AUTOSAR XML (schema 3.1.2)
package /Components/SWC_FARSp
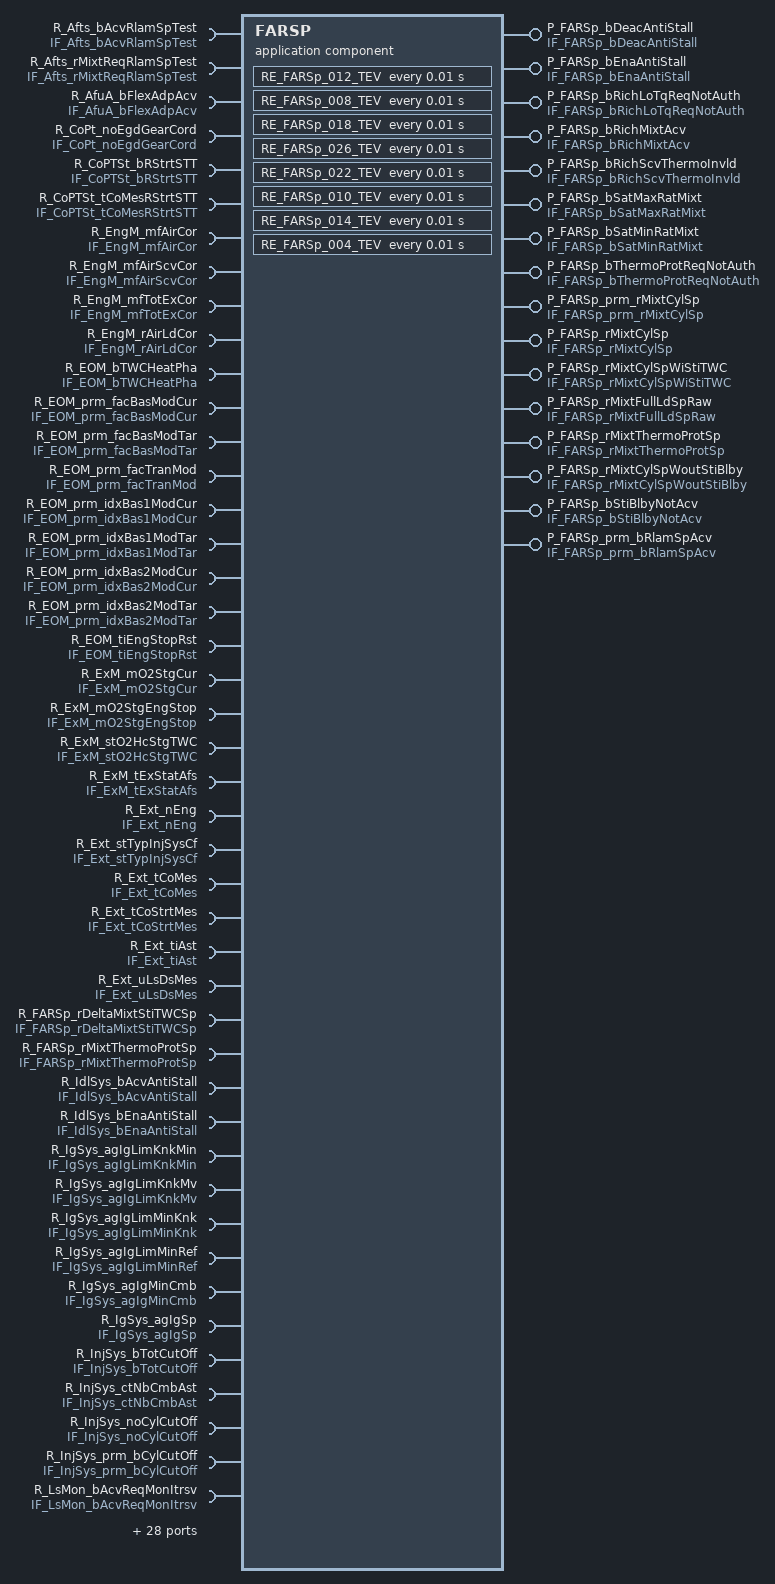
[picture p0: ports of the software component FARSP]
  application software component type FARSP
    71 x require port:
      R_Afts_bAcvRlamSpTest: unqueued-receiver-com-spec{data-element=Afts_bAcvRlamSpTest, init-value=ConstantValue, resync-time=0}, required-interface=IF_Afts_bAcvRlamSpTest  # Receiver of interface IF_Afts_bAcvRlamSpTest - Requirement Reference: [01552_10_01542-FARSp-I145(0)]
      R_Afts_rMixtReqRlamSpTest: unqueued-receiver-com-spec{data-element=Afts_rMixtReqRlamSpTest, init-value=ConstantValue1, resync-time=0}, required-interface=IF_Afts_rMixtReqRlamSpTest  # Receiver of interface IF_Afts_rMixtReqRlamSpTest - Requirement Reference: [01552_10_01542-FARSp-I144(0)]
      R_AfuA_bFlexAdpAcv: unqueued-receiver-com-spec{data-element=AfuA_bFlexAdpAcv, init-value=ConstantValue3, resync-time=0}, required-interface=IF_AfuA_bFlexAdpAcv  # Receiver of interface IF_AfuA_bFlexAdpAcv - Requirement Reference: [01552_10_01542-FARSp-I036(0)]
      R_CoPt_noEgdGearCord: unqueued-receiver-com-spec{data-element=CoPt_noEgdGearCord, init-value=ConstantValue5, resync-time=0}, required-interface=IF_CoPt_noEgdGearCord  # Receiver of interface IF_CoPt_noEgdGearCord - Requirement Reference: [01552_10_01542-FARSp-I099(0)]
      R_CoPTSt_bRStrtSTT: unqueued-receiver-com-spec{data-element=CoPTSt_bRStrtSTT, init-value=ConstantValue7, resync-time=0}, required-interface=IF_CoPTSt_bRStrtSTT  # Receiver of interface IF_CoPTSt_bRStrtSTT - Requirement Reference: [01552_10_01542-FARSp-I043(0)]
      R_CoPTSt_tCoMesRStrtSTT: unqueued-receiver-com-spec{data-element=CoPTSt_tCoMesRStrtSTT, init-value=ConstantValue9, resync-time=0}, required-interface=IF_CoPTSt_tCoMesRStrtSTT  # Receiver of interface IF_CoPTSt_tCoMesRStrtSTT - Requirement Reference: [01552_10_01542-FARSp-I044(1)]
      R_EngM_mfAirCor: unqueued-receiver-com-spec{data-element=EngM_mfAirCor, init-value=ConstantValue11, resync-time=0}, required-interface=IF_EngM_mfAirCor  # Receiver of interface IF_EngM_mfAirCor - Requirement Reference: [01552_10_01542-FARSp-I004(2)]
      R_EngM_mfAirScvCor: unqueued-receiver-com-spec{data-element=EngM_mfAirScvCor, init-value=ConstantValue13, resync-time=0}, required-interface=IF_EngM_mfAirScvCor  # Receiver of interface IF_EngM_mfAirScvCor - Requirement Reference: [01552_10_01542-FARSp-I005(2)]
      R_EngM_mfTotExCor: unqueued-receiver-com-spec{data-element=EngM_mfTotExCor, init-value=ConstantValue15, resync-time=0}, required-interface=IF_EngM_mfTotExCor  # Receiver of interface IF_EngM_mfTotExCor - Requirement Reference: [01552_10_01542-FARSp-I015(0)]
      R_EngM_rAirLdCor: unqueued-receiver-com-spec{data-element=EngM_rAirLdCor, init-value=ConstantValue17, resync-time=0}, required-interface=IF_EngM_rAirLdCor  # Receiver of interface IF_EngM_rAirLdCor - Requirement Reference: [01552_10_01542-FARSp-I006(1)]
      R_EOM_bTWCHeatPha: unqueued-receiver-com-spec{data-element=EOM_bTWCHeatPha, init-value=ConstantValue19, resync-time=0}, required-interface=IF_EOM_bTWCHeatPha  # Receiver of interface IF_EOM_bTWCHeatPha - Requirement Reference: [01552_10_01542-FARSp-I053(0)]
      R_EOM_prm_facBasModCur: unqueued-receiver-com-spec{data-element=EOM_prm_facBasModCur, init-value=ArrayConstantValue, resync-time=0}, required-interface=IF_EOM_prm_facBasModCur  # Receiver of interface IF_EOM_prm_facBasModCur - Requirement Reference: [01552_10_01542-FARSp-I054(2)]
      R_EOM_prm_facBasModTar: unqueued-receiver-com-spec{data-element=EOM_prm_facBasModTar, init-value=ArrayConstantValue21, resync-time=0}, required-interface=IF_EOM_prm_facBasModTar  # Receiver of interface IF_EOM_prm_facBasModTar - Requirement Reference: [01552_10_01542-FARSp-I055(2)]
      R_EOM_prm_facTranMod: unqueued-receiver-com-spec{data-element=EOM_prm_facTranMod, init-value=ArrayConstantValue23, resync-time=0}, required-interface=IF_EOM_prm_facTranMod  # Receiver of interface IF_EOM_prm_facTranMod - Requirement Reference: [01552_10_01542-FARSp-I056(2)]
      R_EOM_prm_idxBas1ModCur: unqueued-receiver-com-spec{data-element=EOM_prm_idxBas1ModCur, init-value=ArrayConstantValue25, resync-time=0}, required-interface=IF_EOM_prm_idxBas1ModCur  # Receiver of interface IF_EOM_prm_idxBas1ModCur - Requirement Reference: [01552_10_01542-FARSp-I057(1)]
      R_EOM_prm_idxBas1ModTar: unqueued-receiver-com-spec{data-element=EOM_prm_idxBas1ModTar, init-value=ArrayConstantValue27, resync-time=0}, required-interface=IF_EOM_prm_idxBas1ModTar  # Receiver of interface IF_EOM_prm_idxBas1ModTar - Requirement Reference: [01552_10_01542-FARSp-I058(1)]
      R_EOM_prm_idxBas2ModCur: unqueued-receiver-com-spec{data-element=EOM_prm_idxBas2ModCur, init-value=ArrayConstantValue29, resync-time=0}, required-interface=IF_EOM_prm_idxBas2ModCur  # Receiver of interface IF_EOM_prm_idxBas2ModCur - Requirement Reference: [01552_10_01542-FARSp-I059(1)]
      R_EOM_prm_idxBas2ModTar: unqueued-receiver-com-spec{data-element=EOM_prm_idxBas2ModTar, init-value=ArrayConstantValue31, resync-time=0}, required-interface=IF_EOM_prm_idxBas2ModTar  # Receiver of interface IF_EOM_prm_idxBas2ModTar - Requirement Reference: [01552_10_01542-FARSp-I060(1)]
      R_EOM_tiEngStopRst: unqueued-receiver-com-spec{data-element=EOM_tiEngStopRst, init-value=ConstantValue33, resync-time=0}, required-interface=IF_EOM_tiEngStopRst  # Receiver of interface IF_EOM_tiEngStopRst - Requirement Reference: [01552_10_01542-FARSp-I042(2)]
      R_ExM_mO2StgCur: unqueued-receiver-com-spec{data-element=ExM_mO2StgCur, init-value=ConstantValue35, resync-time=0}, required-interface=IF_ExM_mO2StgCur  # Receiver of interface IF_ExM_mO2StgCur - Requirement Reference: [01552_10_01542-FARSp-I081(0)]
      R_ExM_mO2StgEngStop: unqueued-receiver-com-spec{data-element=ExM_mO2StgEngStop, init-value=ConstantValue37, resync-time=0}, required-interface=IF_ExM_mO2StgEngStop  # Receiver of interface IF_ExM_mO2StgEngStop - Requirement Reference: [01552_10_01542-FARSp-I082(0)]
      R_ExM_stO2HcStgTWC: unqueued-receiver-com-spec{data-element=ExM_stO2HcStgTWC, init-value=ConstantValue39, resync-time=0}, required-interface=IF_ExM_stO2HcStgTWC  # Receiver of interface IF_ExM_stO2HcStgTWC - Requirement Reference: [01552_10_01542-FARSp-I016(0)]
      R_ExM_tExStatAfs: unqueued-receiver-com-spec{data-element=ExM_tExStatAfs, init-value=ConstantValue41, resync-time=0}, required-interface=IF_ExM_tExStatAfs  # Receiver of interface IF_ExM_tExStatAfs - Requirement Reference: [01552_10_01542-FARSp-I017(1)]
      R_Ext_nEng: unqueued-receiver-com-spec{data-element=Ext_nEng, init-value=ConstantValue43, resync-time=0}, required-interface=IF_Ext_nEng  # Receiver of interface IF_Ext_nEng - Requirement Reference: [01552_10_01542-FARSp-I007(0)]
      R_Ext_stTypInjSysCf: unqueued-receiver-com-spec{data-element=Ext_stTypInjSysCf, init-value=ConstantValue45, resync-time=0}, required-interface=IF_Ext_stTypInjSysCf  # Receiver of interface IF_Ext_stTypInjSysCf - Requirement Reference: [01552_10_01542-FARSp-I008(1)]
      R_Ext_tCoMes: unqueued-receiver-com-spec{data-element=Ext_tCoMes, init-value=ConstantValue47, resync-time=0}, required-interface=IF_Ext_tCoMes  # Receiver of interface IF_Ext_tCoMes - Requirement Reference: [01552_10_01542-FARSp-I045(0)]
      R_Ext_tCoStrtMes: unqueued-receiver-com-spec{data-element=Ext_tCoStrtMes, init-value=ConstantValue49, resync-time=0}, required-interface=IF_Ext_tCoStrtMes  # Receiver of interface IF_Ext_tCoStrtMes - Requirement Reference: [01552_10_01542-FARSp-I046(0)]
      R_Ext_tiAst: unqueued-receiver-com-spec{data-element=Ext_tiAst, init-value=ConstantValue51, resync-time=0}, required-interface=IF_Ext_tiAst  # Receiver of interface IF_Ext_tiAst - Requirement Reference: [01552_10_01542-FARSp-I047(0)]
      R_Ext_uLsDsMes: unqueued-receiver-com-spec{data-element=Ext_uLsDsMes, init-value=ConstantValue53, resync-time=0}, required-interface=IF_Ext_uLsDsMes  # Receiver of interface IF_Ext_uLsDsMes - Requirement Reference: [01552_10_01542-FARSp-I083(1)]
      R_FARSp_rDeltaMixtStiTWCSp: unqueued-receiver-com-spec{data-element=FARSp_rDeltaMixtStiTWCSp, init-value=ConstantValue55, resync-time=0}, required-interface=IF_FARSp_rDeltaMixtStiTWCSp  # Receiver of interface IF_FARSp_rDeltaMixtStiTWCSp - Requirement Reference: [01552_10_01542-FARSp-I109(0)]
      R_FARSp_rMixtThermoProtSp: unqueued-receiver-com-spec{data-element=FARSp_rMixtThermoProtSp, init-value=ConstantValue57, resync-time=0}, required-interface=IF_FARSp_rMixtThermoProtSp  # Receiver of interface IF_FARSp_rMixtThermoProtSp - Requirement Reference: [01552_10_01542-FARSp-I148(0)]
      R_IdlSys_bAcvAntiStall: unqueued-receiver-com-spec{data-element=IdlSys_bAcvAntiStall, init-value=ConstantValue59, resync-time=0}, required-interface=IF_IdlSys_bAcvAntiStall  # Receiver of interface IF_IdlSys_bAcvAntiStall - Requirement Reference: [01552_10_01542-FARSp-I098(0)]
      R_IdlSys_bEnaAntiStall: unqueued-receiver-com-spec{data-element=IdlSys_bEnaAntiStall, init-value=ConstantValue61, resync-time=0}, required-interface=IF_IdlSys_bEnaAntiStall  # Receiver of interface IF_IdlSys_bEnaAntiStall - Requirement Reference: [01552_10_01542-FARSp-I096(0)]
      R_IgSys_agIgLimKnkMin: unqueued-receiver-com-spec{data-element=IgSys_agIgLimKnkMin, init-value=ConstantValue63, resync-time=0}, required-interface=IF_IgSys_agIgLimKnkMin  # Receiver of interface IF_IgSys_agIgLimKnkMin - Requirement Reference: [01552_10_01542-FARSp-I071(1)]
      R_IgSys_agIgLimKnkMv: unqueued-receiver-com-spec{data-element=IgSys_agIgLimKnkMv, init-value=ConstantValue65, resync-time=0}, required-interface=IF_IgSys_agIgLimKnkMv  # Receiver of interface IF_IgSys_agIgLimKnkMv - Requirement Reference: [01552_10_01542-FARSp-I075(0)]
      R_IgSys_agIgLimMinKnk: unqueued-receiver-com-spec{data-element=IgSys_agIgLimMinKnk, init-value=ConstantValue67, resync-time=0}, required-interface=IF_IgSys_agIgLimMinKnk  # Receiver of interface IF_IgSys_agIgLimMinKnk - Requirement Reference: [01552_10_01542-FARSp-I076(0)]
      R_IgSys_agIgLimMinRef: unqueued-receiver-com-spec{data-element=IgSys_agIgLimMinRef, init-value=ConstantValue69, resync-time=0}, required-interface=IF_IgSys_agIgLimMinRef  # Receiver of interface IF_IgSys_agIgLimMinRef - Requirement Reference: [01552_10_01542-FARSp-I077(0)]
      R_IgSys_agIgMinCmb: unqueued-receiver-com-spec{data-element=IgSys_agIgMinCmb, init-value=ConstantValue71, resync-time=0}, required-interface=IF_IgSys_agIgMinCmb  # Receiver of interface IF_IgSys_agIgMinCmb - Requirement Reference: [01552_10_01542-FARSp-I078(0)]
      R_IgSys_agIgSp: unqueued-receiver-com-spec{data-element=IgSys_agIgSp, init-value=ConstantValue73, resync-time=0}, required-interface=IF_IgSys_agIgSp  # Receiver of interface IF_IgSys_agIgSp - Requirement Reference: [01552_10_01542-FARSp-I079(0)]
      R_InjSys_bTotCutOff: unqueued-receiver-com-spec{data-element=InjSys_bTotCutOff, init-value=ConstantValue75, resync-time=0}, required-interface=IF_InjSys_bTotCutOff  # Receiver of interface IF_InjSys_bTotCutOff - Requirement Reference: [01552_10_01542-FARSp-I111(0)]
      R_InjSys_ctNbCmbAst: unqueued-receiver-com-spec{data-element=InjSys_ctNbCmbAst, init-value=ConstantValue77, resync-time=0}, required-interface=IF_InjSys_ctNbCmbAst  # Receiver of interface IF_InjSys_ctNbCmbAst - Requirement Reference: [01552_10_01542-FARSp-I050(0)]
      R_InjSys_noCylCutOff: unqueued-receiver-com-spec{data-element=InjSys_noCylCutOff, init-value=ConstantValue79, resync-time=0}, required-interface=IF_InjSys_noCylCutOff  # Receiver of interface IF_InjSys_noCylCutOff - Requirement Reference: [01552_10_01542-FARSp-I032(0)]
      R_InjSys_prm_bCylCutOff: unqueued-receiver-com-spec{data-element=InjSys_prm_bCylCutOff, init-value=ArrayConstantValue81, resync-time=0}, required-interface=IF_InjSys_prm_bCylCutOff  # Receiver of interface IF_InjSys_prm_bCylCutOff - Requirement Reference: [01552_10_01542-FARSp-I110(1)]
      R_LsMon_bAcvReqMonItrsv: unqueued-receiver-com-spec{data-element=LsMon_bAcvReqMonItrsv, init-value=ConstantValue83, resync-time=0}, required-interface=IF_LsMon_bAcvReqMonItrsv  # Receiver of interface IF_LsMon_bAcvReqMonItrsv - Requirement Reference: [01552_10_01542-FARSp-I147(0)]
      R_LsMon_rMixtReqMonItrsv: unqueued-receiver-com-spec{data-element=LsMon_rMixtReqMonItrsv, init-value=ConstantValue85, resync-time=0}, required-interface=IF_LsMon_rMixtReqMonItrsv  # Receiver of interface IF_LsMon_rMixtReqMonItrsv - Requirement Reference: [01552_10_01542-FARSp-I146(0)]
      R_LsSys_bLsDsMainOxCHeatOk: unqueued-receiver-com-spec{data-element=LsSys_bLsDsMainOxCHeatOk, init-value=ConstantValue87, resync-time=0}, required-interface=IF_LsSys_bLsDsMainOxCHeatOk  # Receiver of interface IF_LsSys_bLsDsMainOxCHeatOk - Requirement Reference: [01552_10_01542-FARSp-I086(0)]
      R_OxC_bAcvReqMonItrsv: unqueued-receiver-com-spec{data-element=OxC_bAcvReqMonItrsv, init-value=ConstantValue89, resync-time=0}, required-interface=IF_OxC_bAcvReqMonItrsv  # Receiver of interface IF_OxC_bAcvReqMonItrsv - Requirement Reference: [01552_10_01542-FARSp-I143(0)]
      R_OxC_rMixtReqMonItrsv: unqueued-receiver-com-spec{data-element=OxC_rMixtReqMonItrsv, init-value=ConstantValue91, resync-time=0}, required-interface=IF_OxC_rMixtReqMonItrsv  # Receiver of interface IF_OxC_rMixtReqMonItrsv - Requirement Reference: [01552_10_01542-FARSp-I108(1)]
      R_TPM_bAcvRichProtOxdTWC: unqueued-receiver-com-spec{data-element=TPM_bAcvRichProtOxdTWC, init-value=ConstantValue93, resync-time=0}, required-interface=IF_TPM_bAcvRichProtOxdTWC  # Receiver of interface IF_TPM_bAcvRichProtOxdTWC - Requirement Reference: [01552_10_01542-FARSp-I022(0)]
      R_TPM_bAcvRichThermoProt: unqueued-receiver-com-spec{data-element=TPM_bAcvRichThermoProt, init-value=ConstantValue95, resync-time=0}, required-interface=IF_TPM_bAcvRichThermoProt  # Receiver of interface IF_TPM_bAcvRichThermoProt - Requirement Reference: [01552_10_01542-FARSp-I023(0)]
      R_TPM_bAirLdLimTExMgr: unqueued-receiver-com-spec{data-element=TPM_bAirLdLimTExMgr, init-value=ConstantValue97, resync-time=0}, required-interface=IF_TPM_bAirLdLimTExMgr  # Receiver of interface IF_TPM_bAirLdLimTExMgr - Requirement Reference: [01552_10_01542-FARSp-I024(0)]
      R_TPM_bExThermoProt: unqueued-receiver-com-spec{data-element=TPM_bExThermoProt, init-value=ConstantValue99, resync-time=0}, required-interface=IF_TPM_bExThermoProt  # Receiver of interface IF_TPM_bExThermoProt - Requirement Reference: [01552_10_01542-FARSp-I072(0)]
      R_TPM_bRichLimScv: unqueued-receiver-com-spec{data-element=TPM_bRichLimScv, init-value=ConstantValue101, resync-time=0}, required-interface=IF_TPM_bRichLimScv  # Receiver of interface IF_TPM_bRichLimScv - Requirement Reference: [01552_10_01542-FARSp-I025(0)]
      R_TPM_rMixtLimMaxAflScv: unqueued-receiver-com-spec{data-element=TPM_rMixtLimMaxAflScv, init-value=ConstantValue103, resync-time=0}, required-interface=IF_TPM_rMixtLimMaxAflScv  # Receiver of interface IF_TPM_rMixtLimMaxAflScv - Requirement Reference: [01552_10_01542-FARSp-I026(0)]
      R_TPM_tExReq: unqueued-receiver-com-spec{data-element=TPM_tExReq, init-value=ConstantValue105, resync-time=0}, required-interface=IF_TPM_tExReq  # Receiver of interface IF_TPM_tExReq - Requirement Reference: [01552_10_01542-FARSp-I027(4)]
      R_TqSys_bAuthRich: unqueued-receiver-com-spec{data-element=TqSys_bAuthRich, init-value=ConstantValue107, resync-time=0}, required-interface=IF_TqSys_bAuthRich  # Receiver of interface IF_TqSys_bAuthRich - Requirement Reference: [01552_10_01542-FARSp-I039(0)]
      R_TWCMgt_bLiOffDone: unqueued-receiver-com-spec{data-element=TWCMgt_bLiOffDone, init-value=ConstantValue109, resync-time=0}, required-interface=IF_TWCMgt_bLiOffDone  # Receiver of interface IF_TWCMgt_bLiOffDone - Requirement Reference: [01552_10_01542-FARSp-I063(0)]
      R_UsThrM_pAirExtEstim: unqueued-receiver-com-spec{data-element=UsThrM_pAirExtEstim, init-value=ConstantValue111, resync-time=0}, required-interface=IF_UsThrM_pAirExtEstim  # Receiver of interface IF_UsThrM_pAirExtEstim - Requirement Reference: [01552_10_01542-FARSp-I040(1)]
      R_CoHeat_bAcvHeatMgt: unqueued-receiver-com-spec{data-element=CoHeat_bAcvHeatMgt, init-value=ConstantValue113, resync-time=0}, required-interface=IF_CoHeat_bAcvHeatMgt  # Receiver of interface IF_CoHeat_bAcvHeatMgt - Requirement Reference: [01552_10_01542-FARSp-I149(0)]
      R_CoHeat_tCoEstim: unqueued-receiver-com-spec{data-element=CoHeat_tCoEstim, init-value=ConstantValue115, resync-time=0}, required-interface=IF_CoHeat_tCoEstim  # Receiver of interface IF_CoHeat_tCoEstim - Requirement Reference: [01552_10_01542-FARSp-I150(0)]
      R_CoHeat_tCoEstimStrt: unqueued-receiver-com-spec{data-element=CoHeat_tCoEstimStrt, init-value=ConstantValue117, resync-time=0}, required-interface=IF_CoHeat_tCoEstimStrt  # Receiver of interface IF_CoHeat_tCoEstimStrt - Requirement Reference: [01552_10_01542-FARSp-I151(0)]
      R_Blby_bAcvStiRich: unqueued-receiver-com-spec{data-element=Blby_bAcvStiRich, init-value=ConstantValue119, resync-time=0}, required-interface=IF_Blby_bAcvStiRich  # Receiver of interface IF_Blby_bAcvStiRich - Requirement Reference: [01552_10_01542-FARSp-I152(0)]
      R_Blby_facStiRich: unqueued-receiver-com-spec{data-element=Blby_facStiRich, init-value=ConstantValue121, resync-time=0}, required-interface=IF_Blby_facStiRich  # Receiver of interface IF_Blby_facStiRich - Requirement Reference: [01552_10_01542-FARSp-I153(0)]
      R_AfuA_rEthWiExct: unqueued-receiver-com-spec{data-element=AfuA_rEthWiExct, init-value=ConstantValue123, resync-time=0}, required-interface=IF_AfuA_rEthWiExct  # Receiver of interface IF_AfuA_rEthWiExct - Requirement Reference: [01552_10_01542-FARSp-I156(0)]
      R_FARSp_bEnaAntiStall: unqueued-receiver-com-spec{data-element=FARSp_bEnaAntiStall, init-value=ConstantValue125, resync-time=0}, required-interface=IF_FARSp_bEnaAntiStall  # Receiver of interface IF_FARSp_bEnaAntiStall - Requirement Reference: [01552_10_01542-FARSp-I158(0)]
      R_EcuM_CurrentMode: required-interface=EcuM_CurrentMode
      R_UCE_stWkuMainRelSt: required-interface=IF_UCE_stWkuMainRelSt
      R_FRM_bLihAstWupSTT: required-interface=FunctionInhibition  # 01552_10_01542-FARSp-I132(0)
      R_FRM_bAcvAflLih: required-interface=FunctionInhibition  # 01552_10_01542-FARSp-I133(0)
      R_FRM_bAcvAfrLih: required-interface=FunctionInhibition  # 01552_10_01542-FARSp-I134(0)
      R_FRM_bAcvAfsLih: required-interface=FunctionInhibition  # 01552_10_01542-FARSp-I135(0)
    16 x provide port:
      P_FARSp_bDeacAntiStall: unqueued-sender-com-spec{data-element=FARSp_bDeacAntiStall, can-invalidate=false, init-value=FARSp_bDeacAntiStall_Cst}, provided-interface=IF_FARSp_bDeacAntiStall
      P_FARSp_bEnaAntiStall: unqueued-sender-com-spec{data-element=FARSp_bEnaAntiStall, can-invalidate=false, init-value=FARSp_bEnaAntiStall_Cst}, provided-interface=IF_FARSp_bEnaAntiStall
      P_FARSp_bRichLoTqReqNotAuth: unqueued-sender-com-spec{data-element=FARSp_bRichLoTqReqNotAuth, can-invalidate=false, init-value=ConstantValue127}, provided-interface=IF_FARSp_bRichLoTqReqNotAuth
      P_FARSp_bRichMixtAcv: unqueued-sender-com-spec{data-element=FARSp_bRichMixtAcv, can-invalidate=false, init-value=FARSp_bRichMixtAcv_Cst}, provided-interface=IF_FARSp_bRichMixtAcv
      P_FARSp_bRichScvThermoInvld: unqueued-sender-com-spec{data-element=FARSp_bRichScvThermoInvld, can-invalidate=false, init-value=FARSp_bRichScvThermoInvld_Cst}, provided-interface=IF_FARSp_bRichScvThermoInvld
      P_FARSp_bSatMaxRatMixt: unqueued-sender-com-spec{data-element=FARSp_bSatMaxRatMixt, can-invalidate=false, init-value=FARSp_bSatMaxRatMixt_Cst}, provided-interface=IF_FARSp_bSatMaxRatMixt
      P_FARSp_bSatMinRatMixt: unqueued-sender-com-spec{data-element=FARSp_bSatMinRatMixt, can-invalidate=false, init-value=FARSp_bSatMinRatMixt_Cst}, provided-interface=IF_FARSp_bSatMinRatMixt
      P_FARSp_bThermoProtReqNotAuth: unqueued-sender-com-spec{data-element=FARSp_bThermoProtReqNotAuth, can-invalidate=false, init-value=FARSp_bThermoProtReqNotAuth_Cst}, provided-interface=IF_FARSp_bThermoProtReqNotAuth
      P_FARSp_prm_rMixtCylSp: unqueued-sender-com-spec{data-element=FARSp_prm_rMixtCylSp, can-invalidate=false, init-value=FARSp_prm_rMixtCylSp_Cst}, provided-interface=IF_FARSp_prm_rMixtCylSp
      P_FARSp_rMixtCylSp: unqueued-sender-com-spec{data-element=FARSp_rMixtCylSp, can-invalidate=false, init-value=ConstantValue129}, provided-interface=IF_FARSp_rMixtCylSp
      P_FARSp_rMixtCylSpWiStiTWC: unqueued-sender-com-spec{data-element=FARSp_rMixtCylSpWiStiTWC, can-invalidate=false, init-value=FARSp_rMixtCylSpWiStiTWC_Cst}, provided-interface=IF_FARSp_rMixtCylSpWiStiTWC
      P_FARSp_rMixtFullLdSpRaw: unqueued-sender-com-spec{data-element=FARSp_rMixtFullLdSpRaw, can-invalidate=false, init-value=FARSp_rMixtFullLdSpRaw_Cst}, provided-interface=IF_FARSp_rMixtFullLdSpRaw
      P_FARSp_rMixtThermoProtSp: unqueued-sender-com-spec{data-element=FARSp_rMixtThermoProtSp, can-invalidate=false, init-value=FARSp_rMixtThermoProtSp_Cst}, provided-interface=IF_FARSp_rMixtThermoProtSp
      P_FARSp_rMixtCylSpWoutStiBlby: unqueued-sender-com-spec{data-element=FARSp_rMixtCylSpWoutStiBlby, can-invalidate=false, init-value=FARSp_rMixtCylSpWoutStiBlby_Cst}, provided-interface=IF_FARSp_rMixtCylSpWoutStiBlby
      P_FARSp_bStiBlbyNotAcv: unqueued-sender-com-spec{data-element=FARSp_bStiBlbyNotAcv, can-invalidate=false, init-value=FARSp_bStiBlbyNotAcv_Cst}, provided-interface=IF_FARSp_bStiBlbyNotAcv
      P_FARSp_prm_bRlamSpAcv: unqueued-sender-com-spec{data-element=FARSp_prm_bRlamSpAcv, can-invalidate=false, init-value=FARSp_prm_bRlamSpAcv_Cst}, provided-interface=IF_FARSp_prm_bRlamSpAcv
    require port R_AfuA_bInvldEthRat: unqueued-receiver-com-spec{data-element=AfuA_bInvldEthRat, init-value=ConstantValue2, resync-time=0}, required-interface=IF_AfuA_bInvldEthRat
  102 x constant specification:
    ArrayConstantValue
      value:
        array specification ArrayConstantValue: type=Array_16_UInt8
          16 x integer literal, all with type=DT_EOM_prm_facBasModCur, value=0:
            Const
            Const{1..15}
    ArrayConstantValue21
      value:
        array specification ArrayConstantValue21: type=Array_16_UInt8_m1
          16 x integer literal, all with type=DT_EOM_prm_facBasModTar, value=0:
            Const
            Const{1..15}
    ArrayConstantValue23
      value:
        array specification ArrayConstantValue23: type=Array_16_UInt8_m2
          16 x integer literal, all with type=DT_EOM_prm_facTranMod, value=0:
            Const
            Const{1..15}
    ArrayConstantValue25
      value:
        array specification ArrayConstantValue25: type=Array_16_UInt8_m3
          16 x integer literal, all with type=DT_EOM_prm_idxBas1ModCur, value=1:
            Const
            Const{1..15}
    ArrayConstantValue27
      value:
        array specification ArrayConstantValue27: type=Array_16_UInt8_m4
          16 x integer literal, all with type=DT_EOM_prm_idxBas1ModTar, value=1:
            Const
            Const{1..15}
    ArrayConstantValue29
      value:
        array specification ArrayConstantValue29: type=Array_16_UInt8_m5
          16 x integer literal, all with type=DT_EOM_prm_idxBas2ModCur, value=1:
            Const
            Const{1..15}
    ArrayConstantValue31
      value:
        array specification ArrayConstantValue31: type=Array_16_UInt8_m6
          16 x integer literal, all with type=DT_EOM_prm_idxBas2ModTar, value=1:
            Const
            Const{1..15}
    ArrayConstantValue81
      value:
        array specification ArrayConstantValue81: type=Array_6_Boolean
          6 x boolean literal, all with type=DT_InjSys_prm_bCylCutOff, value=false:
            Const
            Const{1..5}
    ConstantValue
      value:
        boolean literal ConstantValue: type=DT_Afts_bAcvRlamSpTest, value=false
    ConstantValue1
      value:
        integer literal ConstantValue1: type=DT_Afts_rMixtReqRlamSpTest, value=0
    ConstantValue101
      value:
        boolean literal ConstantValue101: type=DT_TPM_bRichLimScv, value=false
    ConstantValue103
      value:
        integer literal ConstantValue103: type=DT_TPM_rMixtLimMaxAflScv, value=0
    ConstantValue105
      value:
        integer literal ConstantValue105: type=DT_TPM_tExReq, value=7136
    ConstantValue107
      value:
        boolean literal ConstantValue107: type=DT_TqSys_bAuthRich, value=false
    ConstantValue109
      value:
        boolean literal ConstantValue109: type=DT_TWCMgt_bLiOffDone, value=false
    ConstantValue11
      value:
        integer literal ConstantValue11: type=DT_EngM_mfAirCor, value=0
    ConstantValue111
      value:
        integer literal ConstantValue111: type=DT_UsThrM_pAirExtEstim, value=0
    ConstantValue113
      value:
        boolean literal ConstantValue113: type=DT_CoHeat_bAcvHeatMgt, value=false
    ConstantValue115
      value:
        integer literal ConstantValue115: type=DT_CoHeat_tCoEstim, value=-40
    ConstantValue117
      value:
        integer literal ConstantValue117: type=DT_CoHeat_tCoEstimStrt, value=-40
    ConstantValue119
      value:
        boolean literal ConstantValue119: type=DT_Blby_bAcvStiRich, value=false
    ConstantValue121
      value:
        integer literal ConstantValue121: type=DT_Blby_facStiRich, value=32768
    ConstantValue123
      value:
        integer literal ConstantValue123: type=DT_AfuA_rEthWiExct, value=0
    ConstantValue125
      value:
        boolean literal ConstantValue125: type=DT_FARSp_bEnaAntiStall, value=false
    ConstantValue127
      value:
        boolean literal ConstantValue127: type=DT_FARSp_bRichLoTqReqNotAuth, value=false
    ConstantValue129
      value:
        integer literal ConstantValue129: type=DT_FARSp_rMixtCylSp, value=4096
    ConstantValue13
      value:
        integer literal ConstantValue13: type=DT_EngM_mfAirScvCor, value=0
    ConstantValue15
      value:
        integer literal ConstantValue15: type=DT_EngM_mfTotExCor, value=0
    ConstantValue17
      value:
        integer literal ConstantValue17: type=DT_EngM_rAirLdCor, value=0
    ConstantValue19
      value:
        boolean literal ConstantValue19: type=DT_EOM_bTWCHeatPha, value=false
    ConstantValue2
      value:
        boolean literal ConstantValue2: type=DT_AfuA_bInvldEthRat, value=false
    ConstantValue3
      value:
        boolean literal ConstantValue3: type=DT_AfuA_bFlexAdpAcv, value=false
    ConstantValue33
      value:
        integer literal ConstantValue33: type=DT_EOM_tiEngStopRst, value=864000
    ConstantValue35
      value:
        integer literal ConstantValue35: type=DT_ExM_mO2StgCur, value=0
    ConstantValue37
      value:
        integer literal ConstantValue37: type=DT_ExM_mO2StgEngStop, value=0
    ConstantValue39
      value:
        integer literal ConstantValue39: type=DT_ExM_stO2HcStgTWC, value=0
    ConstantValue41
      value:
        integer literal ConstantValue41: type=DT_ExM_tExStatAfs, value=4800
    ConstantValue43
      value:
        integer literal ConstantValue43: type=DT_Ext_nEng, value=0
    ConstantValue45
      value:
        integer literal ConstantValue45: type=DT_Ext_stTypInjSysCf, value=1
    ConstantValue47
      value:
        integer literal ConstantValue47: type=DT_Ext_tCoMes, value=20
    ConstantValue49
      value:
        integer literal ConstantValue49: type=DT_Ext_tCoStrtMes, value=-40
    ConstantValue5
      value:
        integer literal ConstantValue5: type=DT_CoPt_noEgdGearCord, value=0
    ConstantValue51
      value:
        integer literal ConstantValue51: type=DT_Ext_tiAst, value=0
    ConstantValue53
      value:
        integer literal ConstantValue53: type=DT_Ext_uLsDsMes, value=0
    ConstantValue55
      value:
        integer literal ConstantValue55: type=DT_FARSp_rDeltaMixtStiTWCSp, value=0
    ConstantValue57
      value:
        integer literal ConstantValue57: type=DT_FARSp_rMixtThermoProtSp, value=0
    ConstantValue59
      value:
        boolean literal ConstantValue59: type=DT_IdlSys_bAcvAntiStall, value=false
    ConstantValue61
      value:
        boolean literal ConstantValue61: type=DT_IdlSys_bEnaAntiStall, value=false
    ConstantValue63
      value:
        integer literal ConstantValue63: type=DT_IgSys_agIgLimKnkMin, value=192
    ConstantValue65
      value:
        integer literal ConstantValue65: type=DT_IgSys_agIgLimKnkMv, value=96
    ConstantValue67
      value:
        integer literal ConstantValue67: type=DT_IgSys_agIgLimMinKnk, value=0
    ConstantValue69
      value:
        integer literal ConstantValue69: type=DT_IgSys_agIgLimMinRef, value=0
    ConstantValue7
      value:
        boolean literal ConstantValue7: type=DT_CoPTSt_bRStrtSTT, value=false
    ConstantValue71
      value:
        integer literal ConstantValue71: type=DT_IgSys_agIgMinCmb, value=96
    ConstantValue73
      value:
        integer literal ConstantValue73: type=DT_IgSys_agIgSp, value=96
    ConstantValue75
      value:
        boolean literal ConstantValue75: type=DT_InjSys_bTotCutOff, value=false
    ConstantValue77
      value:
        integer literal ConstantValue77: type=DT_InjSys_ctNbCmbAst, value=0
    ConstantValue79
      value:
        integer literal ConstantValue79: type=DT_InjSys_noCylCutOff, value=0
    ConstantValue83
      value:
        boolean literal ConstantValue83: type=DT_LsMon_bAcvReqMonItrsv, value=false
    ConstantValue85
      value:
        integer literal ConstantValue85: type=DT_LsMon_rMixtReqMonItrsv, value=0
    ConstantValue87
      value:
        boolean literal ConstantValue87: type=DT_LsSys_bLsDsMainOxCHeatOk, value=false
    ConstantValue89
      value:
        boolean literal ConstantValue89: type=DT_OxC_bAcvReqMonItrsv, value=false
    ConstantValue9
      value:
        integer literal ConstantValue9: type=DT_CoPTSt_tCoMesRStrtSTT, value=0
    ConstantValue91
      value:
        integer literal ConstantValue91: type=DT_OxC_rMixtReqMonItrsv, value=4096
    ConstantValue93
      value:
        boolean literal ConstantValue93: type=DT_TPM_bAcvRichProtOxdTWC, value=false
    ConstantValue95
      value:
        boolean literal ConstantValue95: type=DT_TPM_bAcvRichThermoProt, value=false
    ConstantValue97
      value:
        boolean literal ConstantValue97: type=DT_TPM_bAirLdLimTExMgr, value=false
    ConstantValue99
      value:
        boolean literal ConstantValue99: type=DT_TPM_bExThermoProt, value=false
    FARSp_bAcvAflScvGDI_Cst
      value:
        boolean literal FARSp_bAcvAflScvGDI_Cst: type=DT_FARSp_bAcvAflScvGDI, value=false
    FARSp_bAcvRatMixtTWCHeat_Cst
      value:
        boolean literal FARSp_bAcvRatMixtTWCHeat_Cst: type=DT_FARSp_bAcvRatMixtTWCHeat, value=false
    FARSp_bAcvRichFullLd_Cst
      value:
        boolean literal FARSp_bAcvRichFullLd_Cst: type=DT_FARSp_bAcvRichFullLd, value=false
    FARSp_bAcvSelCutOffSpcMixt_Cst
      value:
        boolean literal FARSp_bAcvSelCutOffSpcMixt_Cst: type=DT_FARSp_bAcvSelCutOffSpcMixt, value=false
    FARSp_bDeacAntiStall_Cst
      value:
        boolean literal FARSp_bDeacAntiStall_Cst: type=DT_FARSp_bDeacAntiStall, value=false
    FARSp_bEnaAntiStall_Cst
      value:
        boolean literal FARSp_bEnaAntiStall_Cst: type=DT_FARSp_bEnaAntiStall, value=false
    FARSp_bInvldThermoProt_Cst
      value:
        boolean literal FARSp_bInvldThermoProt_Cst: type=DT_FARSp_bInvldThermoProt, value=false
    FARSp_bLihAcv_Cst
      value:
        boolean literal FARSp_bLihAcv_Cst: type=DT_FARSp_bLihAcv, value=false
    FARSp_bRichMixtAcv_Cst
      value:
        boolean literal FARSp_bRichMixtAcv_Cst: type=DT_FARSp_bRichMixtAcv, value=false
    FARSp_bRichScvThermoInvld_Cst
      value:
        boolean literal FARSp_bRichScvThermoInvld_Cst: type=DT_FARSp_bRichScvThermoInvld, value=false
    FARSp_bSatMaxRatMixt_Cst
      value:
        boolean literal FARSp_bSatMaxRatMixt_Cst: type=DT_FARSp_bSatMaxRatMixt, value=false
    FARSp_bSatMinRatMixt_Cst
      value:
        boolean literal FARSp_bSatMinRatMixt_Cst: type=DT_FARSp_bSatMinRatMixt, value=false
    FARSp_bStiBlbyNotAcv_Cst
      value:
        boolean literal FARSp_bStiBlbyNotAcv_Cst: type=DT_FARSp_bStiBlbyNotAcv, value=true
    FARSp_bThermoProtAuth_Cst
      value:
        boolean literal FARSp_bThermoProtAuth_Cst: type=DT_FARSp_bThermoProtAuth, value=false
    FARSp_bThermoProtReqNotAuth_Cst
      value:
        boolean literal FARSp_bThermoProtReqNotAuth_Cst: type=DT_FARSp_bThermoProtReqNotAuth, value=false
    FARSp_prm_bRlamSpAcv_Cst
      value:
        array specification FARSp_prm_bRlamSpAcv_Cst: type=Array_20_Boolean
          20 x boolean literal, all with type=DT_FARSp_prm_bRlamSpAcv, value=false:
            Element_{0..19}
    FARSp_prm_rMixtCylSp_Cst
      value:
        array specification FARSp_prm_rMixtCylSp_Cst: type=Array_6_UInt16
          6 x integer literal, all with type=DT_FARSp_prm_rMixtCylSp, value=4096:
            Element_{0..5}
    FARSp_rMixtAgIgMinProtSp_Cst
      value:
        integer literal FARSp_rMixtAgIgMinProtSp_Cst: type=DT_FARSp_rMixtAgIgMinProtSp, value=0
    FARSp_rMixtAstWupSTTSp_Cst
      value:
        integer literal FARSp_rMixtAstWupSTTSp_Cst: type=DT_FARSp_rMixtAstWupSTTSp, value=0
    FARSp_rMixtAutIgPrvtSp_Cst
      value:
        integer literal FARSp_rMixtAutIgPrvtSp_Cst: type=DT_FARSp_rMixtAutIgPrvtSp, value=0
    FARSp_rMixtBasSp_Cst
      value:
        integer literal FARSp_rMixtBasSp_Cst: type=DT_FARSp_rMixtBasSp, value=0
    FARSp_rMixtCylSpWiStiTWC_Cst
      value:
        integer literal FARSp_rMixtCylSpWiStiTWC_Cst: type=DT_FARSp_rMixtCylSpWiStiTWC, value=4096
    FARSp_rMixtCylSpWoutStiBlby_Cst
      value:
        integer literal FARSp_rMixtCylSpWoutStiBlby_Cst: type=DT_FARSp_rMixtCylSpWoutStiBlby, value=4096
    FARSp_rMixtFullLdSp_Cst
      value:
        integer literal FARSp_rMixtFullLdSp_Cst: type=DT_FARSp_rMixtFullLdSp, value=0
    FARSp_rMixtFullLdSpRaw_Cst
      value:
        integer literal FARSp_rMixtFullLdSpRaw_Cst: type=DT_FARSp_rMixtFullLdSpRaw, value=0
    FARSp_rMixtLihSp_Cst
      value:
        integer literal FARSp_rMixtLihSp_Cst: type=DT_FARSp_rMixtLihSp, value=0
    FARSp_rMixtLoTqReqSp_Cst
      value:
        integer literal FARSp_rMixtLoTqReqSp_Cst: type=DT_FARSp_rMixtLoTqReqSp, value=0
    FARSp_rMixtMaxThermoProt_Cst
      value:
        integer literal FARSp_rMixtMaxThermoProt_Cst: type=DT_FARSp_rMixtMaxThermoProt, value=0
    FARSp_rMixtScvExAfs_Cst
      value:
        integer literal FARSp_rMixtScvExAfs_Cst: type=DT_FARSp_rMixtScvExAfs, value=0
    FARSp_rMixtSelCutOffSp_Cst
      value:
        integer literal FARSp_rMixtSelCutOffSp_Cst: type=DT_FARSp_rMixtSelCutOffSp, value=0
    FARSp_rMixtSpAntiStall_Cst
      value:
        integer literal FARSp_rMixtSpAntiStall_Cst: type=DT_FARSp_rMixtSpAntiStall, value=0
    FARSp_rMixtThermoProtSp_Cst
      value:
        integer literal FARSp_rMixtThermoProtSp_Cst: type=DT_FARSp_rMixtThermoProtSp, value=0
    FARSp_rMixtTWCHeatSp_Cst
      value:
        integer literal FARSp_rMixtTWCHeatSp_Cst: type=DT_FARSp_rMixtTWCHeatSp, value=0
    FARSp_rMixtTWCPurgeSp_Cst
      value:
        integer literal FARSp_rMixtTWCPurgeSp_Cst: type=DT_FARSp_rMixtTWCPurgeSp, value=0
  internal behavior IB_FARSp: component=FARSP
    mode switch event EV_FARSp_003_MSE: start-on-event=RE_FARSp_003_MSE, activation=ENTRY, mode=R_EcuM_CurrentMode.currentMode.RUN
    mode switch event EV_FARSp_017_MSE: start-on-event=RE_FARSp_017_MSE, activation=ENTRY, mode=R_EcuM_CurrentMode.currentMode.RUN
    timing event EV_FARSp_012_TEV: mode-dependency=dependent-on-mode=[R_UCE_stWkuMainRelSt.RCD_stWkuMainRelSt.Invalid, R_UCE_stWkuMainRelSt.RCD_stWkuMainRelSt.PostMainWakeUp, R_UCE_stWkuMainRelSt.RCD_stWkuMainRelSt.PreMainWakeUp], start-on-event=RE_FARSp_012_TEV, period=0.01
    timing event EV_FARSp_008_TEV: mode-dependency=dependent-on-mode=[R_UCE_stWkuMainRelSt.RCD_stWkuMainRelSt.Invalid, R_UCE_stWkuMainRelSt.RCD_stWkuMainRelSt.PostMainWakeUp, R_UCE_stWkuMainRelSt.RCD_stWkuMainRelSt.PreMainWakeUp], start-on-event=RE_FARSp_008_TEV, period=0.01
    mode switch event EV_FARSp_009_MSE: start-on-event=RE_FARSp_009_MSE, activation=ENTRY, mode=R_EcuM_CurrentMode.currentMode.RUN
    timing event EV_FARSp_018_TEV: mode-dependency=dependent-on-mode=[R_UCE_stWkuMainRelSt.RCD_stWkuMainRelSt.Invalid, R_UCE_stWkuMainRelSt.RCD_stWkuMainRelSt.PostMainWakeUp, R_UCE_stWkuMainRelSt.RCD_stWkuMainRelSt.PreMainWakeUp], start-on-event=RE_FARSp_018_TEV, period=0.01
    timing event EV_FARSp_026_TEV: mode-dependency=dependent-on-mode=[R_UCE_stWkuMainRelSt.RCD_stWkuMainRelSt.Invalid, R_UCE_stWkuMainRelSt.RCD_stWkuMainRelSt.PostMainWakeUp, R_UCE_stWkuMainRelSt.RCD_stWkuMainRelSt.PreMainWakeUp], start-on-event=RE_FARSp_026_TEV, period=0.01
    7 x mode switch event, all with activation=ENTRY, mode=R_EcuM_CurrentMode.currentMode.RUN:
      EV_FARSp_021_MSE: start-on-event=RE_FARSp_021_MSE
      EV_FARSp_025_MSE: start-on-event=RE_FARSp_025_MSE
      EV_FARSp_023_MSE: start-on-event=RE_FARSp_023_MSE
      EV_FARSp_007_MSE: start-on-event=RE_FARSp_007_MSE
      EV_FARSp_005_MSE: start-on-event=RE_FARSp_005_MSE
      EV_FARSp_015_MSE: start-on-event=RE_FARSp_015_MSE
      EV_FARSp_013_MSE: start-on-event=RE_FARSp_013_MSE
    4 x timing event, all with mode-dependency=dependent-on-mode=[R_UCE_stWkuMainRelSt.RCD_stWkuMainRelSt.Invalid, R_UCE_stWkuMainRelSt.RCD_stWkuMainRelSt.PostMainWakeUp, R_UCE_stWkuMainRelSt.RCD_stWkuMainRelSt.PreMainWakeUp], period=0.01:
      EV_FARSp_024_TEV: start-on-event=RE_FARSp_024_TEV
      EV_FARSp_002_TEV: start-on-event=RE_FARSp_002_TEV
      EV_FARSp_006_TEV: start-on-event=RE_FARSp_006_TEV
      EV_FARSp_016_TEV: start-on-event=RE_FARSp_016_TEV
    mode switch event EV_FARSp_001_MSE: start-on-event=RE_FARSp_001_MSE, activation=ENTRY, mode=R_EcuM_CurrentMode.currentMode.RUN
    timing event EV_FARSp_022_TEV: mode-dependency=dependent-on-mode=[R_UCE_stWkuMainRelSt.RCD_stWkuMainRelSt.Invalid, R_UCE_stWkuMainRelSt.RCD_stWkuMainRelSt.PostMainWakeUp, R_UCE_stWkuMainRelSt.RCD_stWkuMainRelSt.PreMainWakeUp], start-on-event=RE_FARSp_022_TEV, period=0.01
    timing event EV_FARSp_010_TEV: mode-dependency=dependent-on-mode=[R_UCE_stWkuMainRelSt.RCD_stWkuMainRelSt.Invalid, R_UCE_stWkuMainRelSt.RCD_stWkuMainRelSt.PostMainWakeUp, R_UCE_stWkuMainRelSt.RCD_stWkuMainRelSt.PreMainWakeUp], start-on-event=RE_FARSp_010_TEV, period=0.01
    timing event EV_FARSp_014_TEV: mode-dependency=dependent-on-mode=[R_UCE_stWkuMainRelSt.RCD_stWkuMainRelSt.Invalid, R_UCE_stWkuMainRelSt.RCD_stWkuMainRelSt.PostMainWakeUp, R_UCE_stWkuMainRelSt.RCD_stWkuMainRelSt.PreMainWakeUp], start-on-event=RE_FARSp_014_TEV, period=0.01
    mode switch event EV_FARSp_011_MSE: start-on-event=RE_FARSp_011_MSE, activation=ENTRY, mode=R_EcuM_CurrentMode.currentMode.RUN
    timing event EV_FARSp_004_TEV: mode-dependency=dependent-on-mode=[R_UCE_stWkuMainRelSt.RCD_stWkuMainRelSt.Invalid, R_UCE_stWkuMainRelSt.RCD_stWkuMainRelSt.PostMainWakeUp, R_UCE_stWkuMainRelSt.RCD_stWkuMainRelSt.PreMainWakeUp], start-on-event=RE_FARSp_004_TEV, period=0.01
    20 x inter runnable variable, all with sw-calibration-access=READ-WRITE, communication-approach=EXPLICIT:
      FARSp_rMixtMaxThermoProt: type=DT_FARSp_rMixtMaxThermoProt, init-value=FARSp_rMixtMaxThermoProt_Cst  # [01552_10_01542-FARSp-I805(1)] - Maximum de la consigne de richesse pour la protection composants Dim = 1x1
      FARSp_bAcvAflScvGDI: type=DT_FARSp_bAcvAflScvGDI, init-value=FARSp_bAcvAflScvGDI_Cst  # [01552_10_01542-FARSp-I800(1)] - Booléen d'activation de mélange pauvre à l'échappement en système IDE
      FARSp_rMixtLoTqReqSp: type=DT_FARSp_rMixtLoTqReqSp, init-value=FARSp_rMixtLoTqReqSp_Cst  # [01552_10_01542-FARSp-I818(1)] - Consigne de richesse pour application d'avances agrément
      FARSp_bThermoProtAuth: type=DT_FARSp_bThermoProtAuth, init-value=FARSp_bThermoProtAuth_Cst  # [01552_10_01542-FARSp-I804(1)] - Flag d'autorisation de l'application de la consigne de richesse protection composants Dim = 1x1
      FARSp_rMixtAutIgPrvtSp: type=DT_FARSp_rMixtAutIgPrvtSp, init-value=FARSp_rMixtAutIgPrvtSp_Cst  # [01552_10_01542-FARSp-I817(1)] - Consigne de richesse de préventif CAI
      FARSp_rMixtTWCPurgeSp: type=DT_FARSp_rMixtTWCPurgeSp, init-value=FARSp_rMixtTWCPurgeSp_Cst  # [01552_10_01542-FARSp-I819(1)] - Consigne de richesse de purge catalyseur en redémarrage STT
      FARSp_rMixtAstWupSTTSp: type=DT_FARSp_rMixtAstWupSTTSp, init-value=FARSp_rMixtAstWupSTTSp_Cst  # [01552_10_01542-FARSp-I811(2)] - Consigne de richesse en après départ et mise en action dans les cas de redémarrage normal ou STT
      FARSp_rMixtFullLdSp: type=DT_FARSp_rMixtFullLdSp, init-value=FARSp_rMixtFullLdSp_Cst  # [01552_10_01542-FARSp-I810(1)] - Consigne de richesse brute de volonté conducteur
      FARSp_bInvldThermoProt: type=DT_FARSp_bInvldThermoProt, init-value=FARSp_bInvldThermoProt_Cst  # [01552_10_01542-FARSp-I803(1)] - Flag indiquant une incohérance des consignes de richesse de protection composants Dim = 1x1
      FARSp_rMixtBasSp: type=DT_FARSp_rMixtBasSp, init-value=FARSp_rMixtBasSp_Cst  # [01552_10_01542-FARSp-I801(1)] - Consigne de richesse de base
      FARSp_bAcvRichFullLd: type=DT_FARSp_bAcvRichFullLd, init-value=FARSp_bAcvRichFullLd_Cst  # [01552_10_01542-FARSp-I809(2)] - Activation de la consigne de richesse de volonté conducteur
      FARSp_rMixtScvExAfs: type=DT_FARSp_rMixtScvExAfs, init-value=FARSp_rMixtScvExAfs_Cst  # [01552_10_01542-FARSp-I802(1)] - Consigne de richesse cylindre en IDE lors du balayage pour avoir richesse 1 à l'échappement
      FARSp_bAcvSelCutOffSpcMixt: type=DT_FARSp_bAcvSelCutOffSpcMixt, init-value=FARSp_bAcvSelCutOffSpcMixt_Cst  # [01552_10_01542-FARSp-I807(2)] - Activation de la consigne de richesse en coupure sélective
      FARSp_rMixtLihSp: type=DT_FARSp_rMixtLihSp, init-value=FARSp_rMixtLihSp_Cst  # [01552_10_01542-FARSp-I815(1)] - Consigne de richesse en modes dégradés
      FARSp_bLihAcv: type=DT_FARSp_bLihAcv, init-value=FARSp_bLihAcv_Cst  # [01552_10_01542-FARSp-I814(1)] - Activation de la consigne de richesse en modes dégradés
      FARSp_rMixtTWCHeatSp: type=DT_FARSp_rMixtTWCHeatSp, init-value=FARSp_rMixtTWCHeatSp_Cst  # [01552_10_01542-FARSp-I813(1)] - Consigne de richesse de chauffe catalyseur
      FARSp_rMixtSelCutOffSp: type=DT_FARSp_rMixtSelCutOffSp, init-value=FARSp_rMixtSelCutOffSp_Cst  # [01552_10_01542-FARSp-I808(1)] - Consigne de richesse en coupure sélective
      FARSp_rMixtAgIgMinProtSp: type=DT_FARSp_rMixtAgIgMinProtSp, init-value=FARSp_rMixtAgIgMinProtSp_Cst  # [01552_10_01542-FARSp-I816(1)] - Consigne de richesse pour repousser la limite d'avance mini protection composant en cas de cliquetis
      FARSp_rMixtSpAntiStall: type=DT_FARSp_rMixtSpAntiStall, init-value=FARSp_rMixtSpAntiStall_Cst  # [01552_10_01542-FARSp-I820(1)] - Consigne de richesse spécifique anti-calage
      FARSp_bAcvRatMixtTWCHeat: type=DT_FARSp_bAcvRatMixtTWCHeat, init-value=FARSp_bAcvRatMixtTWCHeat_Cst  # [01552_10_01542-FARSp-I812(2)] - Booléen d'activation de la consigne de richesse de chauffe catalyseur
    per instance memory FARSp_prm_rMixtGasFlexSp: type=FARSp_prm_rMixtGasFlexSp_Array_24_UInt16, type-definition=Array_24_UInt16
    per instance memory FARSp_prm_facGasFlexSp: type=FARSp_prm_facGasFlexSp_Array_24_UInt8, type-definition=Array_24_UInt8
    24 x runnable:
      RE_FARSp_013_MSE: written-variable=[FARSp_bLihAcv, FARSp_rMixtLihSp]  # 01552_10_01542-FARSp-A013(0)
      RE_FARSp_004_TEV: written-variable=[FARSp_rMixtMaxThermoProt, FARSp_bThermoProtAuth, FARSp_bInvldThermoProt]  # 01552_10_01542-FARSp-A004(1)
        9 x data receive point:
          dr_TPM_bAcvRichThermoProt: data-element=R_TPM_bAcvRichThermoProt.TPM_bAcvRichThermoProt
          dr_ExM_stO2HcStgTWC: data-element=R_ExM_stO2HcStgTWC.ExM_stO2HcStgTWC
          dr_TPM_bAcvRichProtOxdTWC: data-element=R_TPM_bAcvRichProtOxdTWC.TPM_bAcvRichProtOxdTWC
          dr_TPM_bRichLimScv: data-element=R_TPM_bRichLimScv.TPM_bRichLimScv
          dr_EngM_mfTotExCor: data-element=R_EngM_mfTotExCor.EngM_mfTotExCor
          dr_TPM_tExReq: data-element=R_TPM_tExReq.TPM_tExReq
          dr_TPM_rMixtLimMaxAflScv: data-element=R_TPM_rMixtLimMaxAflScv.TPM_rMixtLimMaxAflScv
          dr_ExM_tExStatAfs: data-element=R_ExM_tExStatAfs.ExM_tExStatAfs
          dr_TPM_bAirLdLimTExMgr: data-element=R_TPM_bAirLdLimTExMgr.TPM_bAirLdLimTExMgr
        data send point ds_FARSp_rMixtThermoProtSp: data-element=P_FARSp_rMixtThermoProtSp.FARSp_rMixtThermoProtSp
      RE_FARSp_008_TEV: written-variable=[FARSp_bAcvRichFullLd, FARSp_rMixtFullLdSp]  # 01552_10_01542-FARSp-A008(1)
        5 x data receive point:
          dr_UsThrM_pAirExtEstim: data-element=R_UsThrM_pAirExtEstim.UsThrM_pAirExtEstim
          dr_TqSys_bAuthRich: data-element=R_TqSys_bAuthRich.TqSys_bAuthRich
          dr_EngM_rAirLdCor: data-element=R_EngM_rAirLdCor.EngM_rAirLdCor
          dr_Ext_nEng: data-element=R_Ext_nEng.Ext_nEng
          dr_AfuA_bFlexAdpAcv: data-element=R_AfuA_bFlexAdpAcv.AfuA_bFlexAdpAcv
        data send point ds_FARSp_rMixtFullLdSpRaw: data-element=P_FARSp_rMixtFullLdSpRaw.FARSp_rMixtFullLdSpRaw
      RE_FARSp_024_TEV: written-variable=FARSp_rMixtSpAntiStall  # 01552_10_01542-FARSp-A024(1)
        4 x data receive point:
          dr_Ext_tCoMes: data-element=R_Ext_tCoMes.Ext_tCoMes
          dr_IdlSys_bAcvAntiStall: data-element=R_IdlSys_bAcvAntiStall.IdlSys_bAcvAntiStall
          dr_IdlSys_bEnaAntiStall: data-element=R_IdlSys_bEnaAntiStall.IdlSys_bEnaAntiStall
          dr_CoPt_noEgdGearCord: data-element=R_CoPt_noEgdGearCord.CoPt_noEgdGearCord
        data send point ds_FARSp_bEnaAntiStall: data-element=P_FARSp_bEnaAntiStall.FARSp_bEnaAntiStall
        data send point ds_FARSp_bDeacAntiStall: data-element=P_FARSp_bDeacAntiStall.FARSp_bDeacAntiStall
      RE_FARSp_014_TEV: written-variable=[FARSp_bLihAcv, FARSp_rMixtLihSp]  # 01552_10_01542-FARSp-A014(0)
        sync call SC_FRM_bAcvAfsLih: operation=R_FRM_bAcvAfsLih.GetFunctionPermission
        sync call SC_FRM_bAcvAflLih: operation=R_FRM_bAcvAflLih.GetFunctionPermission
        sync call SC_FRM_bAcvAfrLih: operation=R_FRM_bAcvAfrLih.GetFunctionPermission
      RE_FARSp_018_TEV: written-variable=FARSp_rMixtTWCPurgeSp  # 01552_10_01542-FARSp-A018(1)
        10 x data receive point:
          dr_UsThrM_pAirExtEstim: data-element=R_UsThrM_pAirExtEstim.UsThrM_pAirExtEstim
          dr_ExM_mO2StgEngStop: data-element=R_ExM_mO2StgEngStop.ExM_mO2StgEngStop
          dr_Ext_uLsDsMes: data-element=R_Ext_uLsDsMes.Ext_uLsDsMes
          dr_LsSys_bLsDsMainOxCHeatOk: data-element=R_LsSys_bLsDsMainOxCHeatOk.LsSys_bLsDsMainOxCHeatOk
          dr_EngM_rAirLdCor: data-element=R_EngM_rAirLdCor.EngM_rAirLdCor
          dr_CoPTSt_tCoMesRStrtSTT: data-element=R_CoPTSt_tCoMesRStrtSTT.CoPTSt_tCoMesRStrtSTT
          dr_Ext_tiAst: data-element=R_Ext_tiAst.Ext_tiAst
          dr_ExM_mO2StgCur: data-element=R_ExM_mO2StgCur.ExM_mO2StgCur
          dr_CoPTSt_bRStrtSTT: data-element=R_CoPTSt_bRStrtSTT.CoPTSt_bRStrtSTT
          dr_Ext_nEng: data-element=R_Ext_nEng.Ext_nEng
      RE_FARSp_012_TEV: written-variable=[FARSp_rMixtTWCHeatSp, FARSp_bAcvRatMixtTWCHeat]  # 01552_10_01542-FARSp-A012(1)
        11 x data receive point:
          dr_EngM_rAirLdCor: data-element=R_EngM_rAirLdCor.EngM_rAirLdCor
          dr_Ext_nEng: data-element=R_Ext_nEng.Ext_nEng
          dr_EOM_prm_facTranMod: data-element=R_EOM_prm_facTranMod.EOM_prm_facTranMod
          dr_EOM_prm_idxBas2ModCur: data-element=R_EOM_prm_idxBas2ModCur.EOM_prm_idxBas2ModCur
          dr_EOM_prm_idxBas1ModTar: data-element=R_EOM_prm_idxBas1ModTar.EOM_prm_idxBas1ModTar
          dr_EOM_prm_idxBas2ModTar: data-element=R_EOM_prm_idxBas2ModTar.EOM_prm_idxBas2ModTar
          dr_TWCMgt_bLiOffDone: data-element=R_TWCMgt_bLiOffDone.TWCMgt_bLiOffDone
          dr_EOM_prm_idxBas1ModCur: data-element=R_EOM_prm_idxBas1ModCur.EOM_prm_idxBas1ModCur
          dr_EOM_prm_facBasModCur: data-element=R_EOM_prm_facBasModCur.EOM_prm_facBasModCur
          dr_EOM_prm_facBasModTar: data-element=R_EOM_prm_facBasModTar.EOM_prm_facBasModTar
          dr_EOM_bTWCHeatPha: data-element=R_EOM_bTWCHeatPha.EOM_bTWCHeatPha
      RE_FARSp_017_MSE: written-variable=FARSp_rMixtTWCPurgeSp  # 01552_10_01542-FARSp-A017(1)
      RE_FARSp_009_MSE: written-variable=FARSp_rMixtAstWupSTTSp  # 01552_10_01542-FARSp-A009(0)
      RE_FARSp_023_MSE: written-variable=FARSp_rMixtSpAntiStall  # 01552_10_01542-FARSp-A023(0)
        data send point ds_FARSp_bDeacAntiStall: data-element=P_FARSp_bDeacAntiStall.FARSp_bDeacAntiStall
        data send point ds_FARSp_bEnaAntiStall: data-element=P_FARSp_bEnaAntiStall.FARSp_bEnaAntiStall
      RE_FARSp_021_MSE  # 01552_10_01542-FARSp-A021(2)
        12 x data send point:
          ds_FARSp_bRichLoTqReqNotAuth: data-element=P_FARSp_bRichLoTqReqNotAuth.FARSp_bRichLoTqReqNotAuth
          ds_FARSp_prm_rMixtCylSp: data-element=P_FARSp_prm_rMixtCylSp.FARSp_prm_rMixtCylSp
          ds_FARSp_prm_bRlamSpAcv: data-element=P_FARSp_prm_bRlamSpAcv.FARSp_prm_bRlamSpAcv
          ds_FARSp_rMixtCylSpWoutStiBlby: data-element=P_FARSp_rMixtCylSpWoutStiBlby.FARSp_rMixtCylSpWoutStiBlby
          ds_FARSp_bRichScvThermoInvld: data-element=P_FARSp_bRichScvThermoInvld.FARSp_bRichScvThermoInvld
          ds_FARSp_bSatMinRatMixt: data-element=P_FARSp_bSatMinRatMixt.FARSp_bSatMinRatMixt
          ds_FARSp_bRichMixtAcv: data-element=P_FARSp_bRichMixtAcv.FARSp_bRichMixtAcv
          ds_FARSp_bStiBlbyNotAcv: data-element=P_FARSp_bStiBlbyNotAcv.FARSp_bStiBlbyNotAcv
          ds_FARSp_bSatMaxRatMixt: data-element=P_FARSp_bSatMaxRatMixt.FARSp_bSatMaxRatMixt
          ds_FARSp_rMixtCylSpWiStiTWC: data-element=P_FARSp_rMixtCylSpWiStiTWC.FARSp_rMixtCylSpWiStiTWC
          ds_FARSp_bThermoProtReqNotAuth: data-element=P_FARSp_bThermoProtReqNotAuth.FARSp_bThermoProtReqNotAuth
          ds_FARSp_rMixtCylSp: data-element=P_FARSp_rMixtCylSp.FARSp_rMixtCylSp
      RE_FARSp_015_MSE: written-variable=[FARSp_rMixtAutIgPrvtSp, FARSp_rMixtAgIgMinProtSp, FARSp_rMixtLoTqReqSp]  # 01552_10_01542-FARSp-A015(0)
      RE_FARSp_026_TEV  # 01552_10_01542-FARSp-A026(0)
        16 x data receive point:
          dr_EOM_prm_idxBas1ModTar: data-element=R_EOM_prm_idxBas1ModTar.EOM_prm_idxBas1ModTar
          dr_EOM_prm_idxBas2ModCur: data-element=R_EOM_prm_idxBas2ModCur.EOM_prm_idxBas2ModCur
          dr_AfuA_bInvldEthRat: data-element=R_AfuA_bInvldEthRat.AfuA_bInvldEthRat
          dr_AfuA_rEthWiExct: data-element=R_AfuA_rEthWiExct.AfuA_rEthWiExct
          dr_CoPTSt_bRStrtSTT: data-element=R_CoPTSt_bRStrtSTT.CoPTSt_bRStrtSTT
          dr_InjSys_ctNbCmbAst: data-element=R_InjSys_ctNbCmbAst.InjSys_ctNbCmbAst
          dr_EOM_prm_facBasModCur: data-element=R_EOM_prm_facBasModCur.EOM_prm_facBasModCur
          dr_Ext_tCoStrtMes: data-element=R_Ext_tCoStrtMes.Ext_tCoStrtMes
          dr_CoPTSt_tCoMesRStrtSTT: data-element=R_CoPTSt_tCoMesRStrtSTT.CoPTSt_tCoMesRStrtSTT
          dr_EngM_rAirLdCor: data-element=R_EngM_rAirLdCor.EngM_rAirLdCor
          dr_EOM_prm_facTranMod: data-element=R_EOM_prm_facTranMod.EOM_prm_facTranMod
          dr_EOM_prm_facBasModTar: data-element=R_EOM_prm_facBasModTar.EOM_prm_facBasModTar
          dr_Ext_nEng: data-element=R_Ext_nEng.Ext_nEng
          dr_EOM_prm_idxBas1ModCur: data-element=R_EOM_prm_idxBas1ModCur.EOM_prm_idxBas1ModCur
          dr_Ext_tCoMes: data-element=R_Ext_tCoMes.Ext_tCoMes
          dr_EOM_prm_idxBas2ModTar: data-element=R_EOM_prm_idxBas2ModTar.EOM_prm_idxBas2ModTar
      RE_FARSp_022_TEV: read-variable=[FARSp_bLihAcv, FARSp_rMixtLoTqReqSp, FARSp_rMixtBasSp, FARSp_rMixtAgIgMinProtSp, FARSp_rMixtSelCutOffSp, FARSp_bAcvSelCutOffSpcMixt, FARSp_bAcvRatMixtTWCHeat, FARSp_rMixtScvExAfs, FARSp_rMixtAstWupSTTSp, FARSp_bThermoProtAuth, FARSp_rMixtFullLdSp, FARSp_rMixtSpAntiStall, FARSp_bAcvAflScvGDI, FARSp_rMixtTWCHeatSp, FARSp_rMixtTWCPurgeSp, FARSp_rMixtLihSp, FARSp_bAcvRichFullLd, FARSp_rMixtMaxThermoProt, FARSp_rMixtAutIgPrvtSp, FARSp_bInvldThermoProt]  # 01552_10_01542-FARSp-A022(3)
        15 x data receive point:
          dr_FARSp_bEnaAntiStall: data-element=R_FARSp_bEnaAntiStall.FARSp_bEnaAntiStall
          dr_InjSys_prm_bCylCutOff: data-element=R_InjSys_prm_bCylCutOff.InjSys_prm_bCylCutOff
          dr_FARSp_rDeltaMixtStiTWCSp: data-element=R_FARSp_rDeltaMixtStiTWCSp.FARSp_rDeltaMixtStiTWCSp
          dr_LsMon_bAcvReqMonItrsv: data-element=R_LsMon_bAcvReqMonItrsv.LsMon_bAcvReqMonItrsv
          dr_Blby_facStiRich: data-element=R_Blby_facStiRich.Blby_facStiRich
          dr_EngM_rAirLdCor: data-element=R_EngM_rAirLdCor.EngM_rAirLdCor
          dr_OxC_bAcvReqMonItrsv: data-element=R_OxC_bAcvReqMonItrsv.OxC_bAcvReqMonItrsv
          dr_Blby_bAcvStiRich: data-element=R_Blby_bAcvStiRich.Blby_bAcvStiRich
          dr_Ext_nEng: data-element=R_Ext_nEng.Ext_nEng
          dr_Afts_rMixtReqRlamSpTest: data-element=R_Afts_rMixtReqRlamSpTest.Afts_rMixtReqRlamSpTest
          dr_FARSp_rMixtThermoProtSp: data-element=R_FARSp_rMixtThermoProtSp.FARSp_rMixtThermoProtSp
          dr_OxC_rMixtReqMonItrsv: data-element=R_OxC_rMixtReqMonItrsv.OxC_rMixtReqMonItrsv
          dr_LsMon_rMixtReqMonItrsv: data-element=R_LsMon_rMixtReqMonItrsv.LsMon_rMixtReqMonItrsv
          dr_InjSys_bTotCutOff: data-element=R_InjSys_bTotCutOff.InjSys_bTotCutOff
          dr_Afts_bAcvRlamSpTest: data-element=R_Afts_bAcvRlamSpTest.Afts_bAcvRlamSpTest
        12 x data send point:
          ds_FARSp_bStiBlbyNotAcv: data-element=P_FARSp_bStiBlbyNotAcv.FARSp_bStiBlbyNotAcv
          ds_FARSp_rMixtCylSp: data-element=P_FARSp_rMixtCylSp.FARSp_rMixtCylSp
          ds_FARSp_rMixtCylSpWiStiTWC: data-element=P_FARSp_rMixtCylSpWiStiTWC.FARSp_rMixtCylSpWiStiTWC
          ds_FARSp_bRichMixtAcv: data-element=P_FARSp_bRichMixtAcv.FARSp_bRichMixtAcv
          ds_FARSp_bRichLoTqReqNotAuth: data-element=P_FARSp_bRichLoTqReqNotAuth.FARSp_bRichLoTqReqNotAuth
          ds_FARSp_bRichScvThermoInvld: data-element=P_FARSp_bRichScvThermoInvld.FARSp_bRichScvThermoInvld
          ds_FARSp_bSatMinRatMixt: data-element=P_FARSp_bSatMinRatMixt.FARSp_bSatMinRatMixt
          ds_FARSp_rMixtCylSpWoutStiBlby: data-element=P_FARSp_rMixtCylSpWoutStiBlby.FARSp_rMixtCylSpWoutStiBlby
          ds_FARSp_prm_rMixtCylSp: data-element=P_FARSp_prm_rMixtCylSp.FARSp_prm_rMixtCylSp
          ds_FARSp_prm_bRlamSpAcv: data-element=P_FARSp_prm_bRlamSpAcv.FARSp_prm_bRlamSpAcv
          ds_FARSp_bThermoProtReqNotAuth: data-element=P_FARSp_bThermoProtReqNotAuth.FARSp_bThermoProtReqNotAuth
          ds_FARSp_bSatMaxRatMixt: data-element=P_FARSp_bSatMaxRatMixt.FARSp_bSatMaxRatMixt
      RE_FARSp_001_MSE: written-variable=[FARSp_rMixtBasSp, FARSp_rMixtScvExAfs, FARSp_bAcvAflScvGDI]  # 01552_10_01542-FARSp-A001(0)
      RE_FARSp_016_TEV: written-variable=[FARSp_rMixtAutIgPrvtSp, FARSp_rMixtLoTqReqSp, FARSp_rMixtAgIgMinProtSp]  # 01552_10_01542-FARSp-A016(1)
        9 x data receive point:
          dr_IgSys_agIgSp: data-element=R_IgSys_agIgSp.IgSys_agIgSp
          dr_IgSys_agIgLimMinRef: data-element=R_IgSys_agIgLimMinRef.IgSys_agIgLimMinRef
          dr_IgSys_agIgLimMinKnk: data-element=R_IgSys_agIgLimMinKnk.IgSys_agIgLimMinKnk
          dr_IgSys_agIgLimKnkMv: data-element=R_IgSys_agIgLimKnkMv.IgSys_agIgLimKnkMv
          dr_IgSys_agIgLimKnkMin: data-element=R_IgSys_agIgLimKnkMin.IgSys_agIgLimKnkMin
          dr_TPM_bExThermoProt: data-element=R_TPM_bExThermoProt.TPM_bExThermoProt
          dr_Ext_nEng: data-element=R_Ext_nEng.Ext_nEng
          dr_IgSys_agIgMinCmb: data-element=R_IgSys_agIgMinCmb.IgSys_agIgMinCmb
          dr_EngM_rAirLdCor: data-element=R_EngM_rAirLdCor.EngM_rAirLdCor
      RE_FARSp_010_TEV: written-variable=FARSp_rMixtAstWupSTTSp  # 01552_10_01542-FARSp-A010(2)
        10 x data receive point:
          dr_EOM_tiEngStopRst: data-element=R_EOM_tiEngStopRst.EOM_tiEngStopRst
          dr_Ext_tiAst: data-element=R_Ext_tiAst.Ext_tiAst
          dr_CoHeat_tCoEstimStrt: data-element=R_CoHeat_tCoEstimStrt.CoHeat_tCoEstimStrt
          dr_CoPTSt_tCoMesRStrtSTT: data-element=R_CoPTSt_tCoMesRStrtSTT.CoPTSt_tCoMesRStrtSTT
          dr_CoHeat_bAcvHeatMgt: data-element=R_CoHeat_bAcvHeatMgt.CoHeat_bAcvHeatMgt
          dr_CoPTSt_bRStrtSTT: data-element=R_CoPTSt_bRStrtSTT.CoPTSt_bRStrtSTT
          dr_CoHeat_tCoEstim: data-element=R_CoHeat_tCoEstim.CoHeat_tCoEstim
          dr_Ext_tCoMes: data-element=R_Ext_tCoMes.Ext_tCoMes
          dr_Ext_tCoStrtMes: data-element=R_Ext_tCoStrtMes.Ext_tCoStrtMes
          dr_InjSys_ctNbCmbAst: data-element=R_InjSys_ctNbCmbAst.InjSys_ctNbCmbAst
        sync call SC_FRM_bLihAstWupSTT: operation=R_FRM_bLihAstWupSTT.GetFunctionPermission
      RE_FARSp_006_TEV: written-variable=[FARSp_rMixtSelCutOffSp, FARSp_bAcvSelCutOffSpcMixt]  # 01552_10_01542-FARSp-A006(1)
        data receive point dr_EngM_mfTotExCor: data-element=R_EngM_mfTotExCor.EngM_mfTotExCor
        data receive point dr_InjSys_noCylCutOff: data-element=R_InjSys_noCylCutOff.InjSys_noCylCutOff
      RE_FARSp_003_MSE: written-variable=[FARSp_bInvldThermoProt, FARSp_rMixtMaxThermoProt, FARSp_bThermoProtAuth]  # 01552_10_01542-FARSp-A003(0)
        data send point ds_FARSp_rMixtThermoProtSp: data-element=P_FARSp_rMixtThermoProtSp.FARSp_rMixtThermoProtSp
      RE_FARSp_011_MSE: written-variable=[FARSp_bAcvRatMixtTWCHeat, FARSp_rMixtTWCHeatSp]  # 01552_10_01542-FARSp-A011(0)
      RE_FARSp_025_MSE  # 01552_10_01542-FARSp-A025(0)
      RE_FARSp_005_MSE: written-variable=[FARSp_rMixtSelCutOffSp, FARSp_bAcvSelCutOffSpcMixt]  # 01552_10_01542-FARSp-A005(0)
      RE_FARSp_007_MSE: written-variable=[FARSp_rMixtFullLdSp, FARSp_bAcvRichFullLd]  # 01552_10_01542-FARSp-A007(0)
        data send point ds_FARSp_rMixtFullLdSpRaw: data-element=P_FARSp_rMixtFullLdSpRaw.FARSp_rMixtFullLdSpRaw
      RE_FARSp_002_TEV: written-variable=[FARSp_bAcvAflScvGDI, FARSp_rMixtBasSp, FARSp_rMixtScvExAfs]  # 01552_10_01542-FARSp-A002(0)
        5 x data receive point:
          dr_Ext_nEng: data-element=R_Ext_nEng.Ext_nEng
          dr_EngM_mfAirScvCor: data-element=R_EngM_mfAirScvCor.EngM_mfAirScvCor
          dr_EngM_mfAirCor: data-element=R_EngM_mfAirCor.EngM_mfAirCor
          dr_Ext_stTypInjSysCf: data-element=R_Ext_stTypInjSysCf.Ext_stTypInjSysCf
          dr_EngM_rAirLdCor: data-element=R_EngM_rAirLdCor.EngM_rAirLdCor
  swc implementation Imp_FARSp: programming-language=C, behavior=IB_FARSp
    code-descriptors:
      code CodeDescriptor: type=SRC
        53 x xfile:
          FARSp_002_TEV_fct_h: url=FARSp_002_TEV_fct.h
          FARSp_010_calibrations_c: url=FARSp_010_calibrations.c
          FARSp_002_calibrations_c: url=FARSp_002_calibrations.c
          FARSp_022_TEV_fct_h: url=FARSp_022_TEV_fct.h
          FARSp_018_calibrations_h: url=FARSp_018_calibrations.h
          FARSp_018_TEV_fct_h: url=FARSp_018_TEV_fct.h
          FARSp_024_TEV_fct_c: url=FARSp_024_TEV_fct.c
          FARSp_024_calibrations_c: url=FARSp_024_calibrations.c
          FARSp_MemMap_h: url=FARSp_MemMap.h
          FARSp_024_calibrations_h: url=FARSp_024_calibrations.h
          FARSp_012_TEV_fct_c: url=FARSp_012_TEV_fct.c
          FARSp_010_TEV_fct_c: url=FARSp_010_TEV_fct.c
          FARSp_018_calibrations_c: url=FARSp_018_calibrations.c
          FARSp_006_TEV_fct_c: url=FARSp_006_TEV_fct.c
          FARSp_008_calibrations_c: url=FARSp_008_calibrations.c
          FARSp_h: url=FARSp.h
          FARSp_010_calibrations_h: url=FARSp_010_calibrations.h
          FARSp_016_calibrations_h: url=FARSp_016_calibrations.h
          FARSp_026_TEV_fct_c: url=FARSp_026_TEV_fct.c
          FARSp_004_TEV_fct_c: url=FARSp_004_TEV_fct.c
          FARSp_006_TEV_fct_h: url=FARSp_006_TEV_fct.h
          FARSp_024_TEV_fct_h: url=FARSp_024_TEV_fct.h
          FARSp_004_TEV_fct_h: url=FARSp_004_TEV_fct.h
          FARSp_016_TEV_fct_h: url=FARSp_016_TEV_fct.h
          FARSp_014_calibrations_h: url=FARSp_014_calibrations.h
          FARSp_RE026_calibrations_h: url=FARSp_RE026_calibrations.h
          FARSp_008_calibrations_h: url=FARSp_008_calibrations.h
          FARSp_012_calibrations_c: url=FARSp_012_calibrations.c
          FARSp_012_calibrations_h: url=FARSp_012_calibrations.h
          FARSp_014_calibrations_c: url=FARSp_014_calibrations.c
          FARSp_004_calibrations_c: url=FARSp_004_calibrations.c
          FARSp_006_calibrations_c: url=FARSp_006_calibrations.c
          FARSp_006_calibrations_h: url=FARSp_006_calibrations.h
          FARSp_022_calibrations_h: url=FARSp_022_calibrations.h
          FARSp_002_calibrations_h: url=FARSp_002_calibrations.h
          FARSp_014_TEV_fct_h: url=FARSp_014_TEV_fct.h
          FARSp_026_TEV_fct_h: url=FARSp_026_TEV_fct.h
          FARSp_012_TEV_fct_h: url=FARSp_012_TEV_fct.h
          FARSp_022_TEV_fct_c: url=FARSp_022_TEV_fct.c
          FARSp_016_calibrations_c: url=FARSp_016_calibrations.c
          FARSp_018_TEV_fct_c: url=FARSp_018_TEV_fct.c
          FARSp_RE026_calibrations_c: url=FARSp_RE026_calibrations.c
          FARSp_c: url=FARSp.c
          FARSp_calibrations_c: url=FARSp_calibrations.c
          FARSp_010_TEV_fct_h: url=FARSp_010_TEV_fct.h
          FARSp_016_TEV_fct_c: url=FARSp_016_TEV_fct.c
          FARSp_002_TEV_fct_c: url=FARSp_002_TEV_fct.c
          FARSp_calibrations_h: url=FARSp_calibrations.h
          FARSp_004_calibrations_h: url=FARSp_004_calibrations.h
          FARSp_022_calibrations_c: url=FARSp_022_calibrations.c
          FARSp_008_TEV_fct_c: url=FARSp_008_TEV_fct.c
          FARSp_008_TEV_fct_h: url=FARSp_008_TEV_fct.h
          FARSp_014_TEV_fct_c: url=FARSp_014_TEV_fct.c
package /Components/SWC_FARSp/FARSp_IRVDatatypes
  7 x boolean type, all with base-type=boolean:
    DT_FARSp_bAcvAflScvGDI
    DT_FARSp_bAcvRatMixtTWCHeat
    DT_FARSp_bAcvRichFullLd
    DT_FARSp_bAcvSelCutOffSpcMixt
    DT_FARSp_bInvldThermoProt
    DT_FARSp_bLihAcv
    DT_FARSp_bThermoProtAuth
  13 x integer type, all with base-type=uint16, lower-limit=0, upper-limit=65535:
    DT_FARSp_rMixtAgIgMinProtSp
    DT_FARSp_rMixtAstWupSTTSp
    DT_FARSp_rMixtAutIgPrvtSp
    DT_FARSp_rMixtBasSp
    DT_FARSp_rMixtFullLdSp
    DT_FARSp_rMixtLihSp
    DT_FARSp_rMixtLoTqReqSp
    DT_FARSp_rMixtMaxThermoProt
    DT_FARSp_rMixtScvExAfs
    DT_FARSp_rMixtSelCutOffSp
    DT_FARSp_rMixtSpAntiStall
    DT_FARSp_rMixtTWCHeatSp
    DT_FARSp_rMixtTWCPurgeSp
package /Components/SWC_FARSp/FARSp_PIMDatatypes
  array type Array_24_UInt16
    element ArrayElement: base-type=uint16, type=UInt16, max-number-of-elements=24
  array type Array_24_UInt8
    element ArrayElement: base-type=uint8, type=UInt8, max-number-of-elements=24
